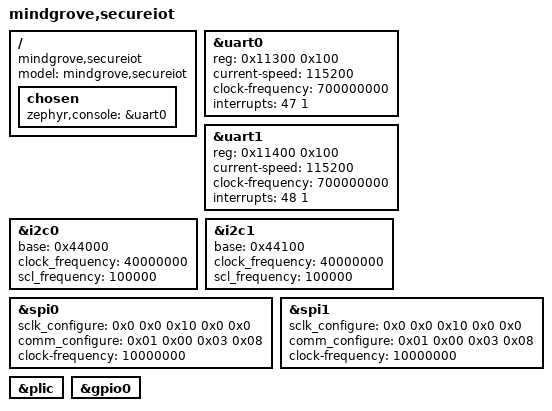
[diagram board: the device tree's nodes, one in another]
/dts-v1/;

#include <secure-iot/riscv64-secure-iot.dtsi>

/ {
	model = "mindgrove,secureiot";
	compatible = "mindgrove,secureiot";

chosen {
		zephyr,console = &uart0;
	};
};

&uart0 {
	status = "okay";
	reg = <0x11300 0x100>;
	current-speed = <115200>;
	clock-frequency = <700000000>;
	interrupts = <47 1>; 
	interrupt-names = "txnrx";
};

&uart1 {
	status = "okay";
	reg = <0x11400 0x100>;
	current-speed = <115200>;
	clock-frequency = <700000000>;
	interrupts = <48 1>; 
	interrupt-names = "txnrx";
};

&i2c0 {
	status = "ok";
	base = <0x44000>;
	clock_frequency = <40000000>;
	scl_frequency = <100000>;
};
&i2c1 {
	status = "ok";
	base = <0x44100>;
	clock_frequency = <40000000>;
	scl_frequency = <100000>;
};
&spi0 {
		status = "okay";
		sclk_configure = <0x0 0x0 0x10 0x0 0x0>;
        comm_configure = <0x01 0x00 0x03 0x08>;
		clock-frequency = <10000000>;
        // cs-gpios = <&gpio0 10 0>;

};

&spi1 {
		status = "okay";
		sclk_configure = <0x0 0x0 0x10 0x0 0x0>;
        comm_configure = <0x01 0x00 0x03 0x08>;
		clock-frequency = <10000000>;
        // cs-gpios = <&gpio0 3 GPIO_ACTIVE_HIGH>;

};

&plic {
	status = "okay";
};

&gpio0 {
	status = "okay";
};
